# R7KA8P1AD register map
Vendor: Renesas Electronics Corporation; Series: RA8; File version: 1.10.02
CPU: CM85 r0p2, little endian, MPU, FPU, VTOR, 4 interrupt priority bits, 96 interrupts
Registers are 32-bit, read-write, reset 0x0 unless marked. A register's access mark holds for its fields unless they carry their own. Offsets are from the block's base; [hi:lo] are bit positions; lines under a group give offsets from that group; {n}, {i} and the like mark numbered series; 'fields as' and 'values as' point back to an identical list.

## RMAC0 — Ethernet MAC
Base 0x403CB000
Same registers: RMAC1 0x403CD000, RMAC0_NS 0x503CB000, RMAC1_NS 0x503CD000
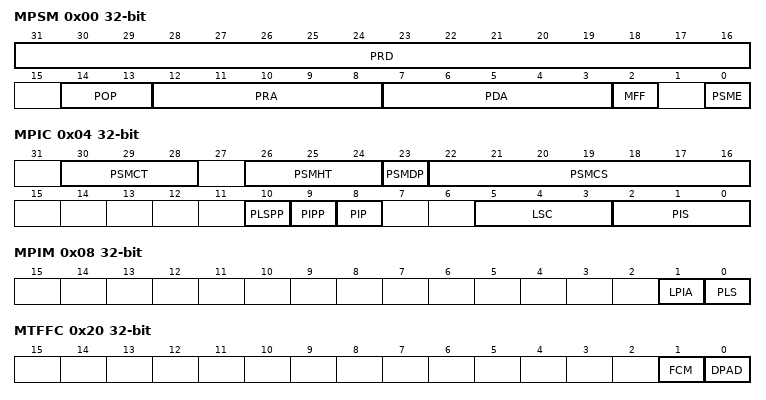
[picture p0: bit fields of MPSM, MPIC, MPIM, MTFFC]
0x00 MPSM — PHY Station Management Register
  [31:16] PRD — PHY Register Data
  [14:13] POP — PHY Operation Code
    1=Write Frame; 2=Read Frame; other=Others (Reserved(0 0 or 1 1 should not be set when MPSM.MFF = 0))
  [12:8] PRA — PHY Register Address
  [7:3] PDA — PHY Device Address
  [2] MFF — Management Frame Format
    0=Normal management frame format defined in Clause 22 of IEEE802.3 Describe “MDIO” in this document; 1=Extension management frame format defined in Clause 45 of IEEE802.3 Describe “eMDIO” in this document
  [0] PSME — PHY Station Management Enable
    0=PHY register access is not on progress; 1=PHY register access is requested and on progress
0x04 MPIC — PHY Interfaces Configuration Register
  [30:28] PSMCT — PHY Station Management Capture Time Adjustment
    0=No adjusted capture time (i.e. capture MDI at the rising edge of MDC); 1=Capture before 1 clk cycle
  [26:24] PSMHT — PHY Station Management Hold Time Adjustment
    0=No adjusted hold time (i.e. change MDO at the rising edge of MDC); 1=1 clk cycle extra hold time
  [23] PSMDP — PHY Station Management Disable Preamble
    0=PHY Station Management Preamble enabled; 1=PHY Station Management Preamble disabled
  [22:16] PSMCS — PHY Station Management Clock Selection
  [10] PLSPP — PHY Link Status Pin Plugged
    0=Unplugged; 1=Plugged
  [9] PIPP — PHY Interrupt Pin Plugged
    0=Unplugged; 1=Plugged
  [8] PIP — PHY Interrupt Polarity
    0=PHY interrupt is active low (default); 1=PHY interrupt is active high
  [5:3] LSC — Link Speed Configuration
    0=10mbps; 1=100mbps; 2=1gbps
  [2:0] PIS — PHY Interface Select
    0=MII; 2=GMII
0x08 MPIM ro — PHY Interfaces Monitoring Register
  [1] LPIA — LPI Active
    0=No LPI; 1=LPI active
  [0] PLS — PHY Link Status Flag
    0=PHY link signal is at the low level; 1=PHY link signal is at the high level
0x10 MIOC — I/O Configuration Register
  [0] MIOC0 — I/O Configuration 0
    0=Normal mode. clk_phy_tx and clk_phy_rx are provided.; 1=Emergency clock recovery mode. clk_phy_tx and clk_phy_rx are provided free-run clock (clk_common). (So transmission is not possible in this state.)
0x20 MTFFC — Transmission Frame Format Configuration Register
  [1] FCM — Flow Control Mode
    0=PAUSE; 1=PFC
  [0] DPAD — Data Padding Disable
    0=Padding is inserted; 1=Padding is not inserted
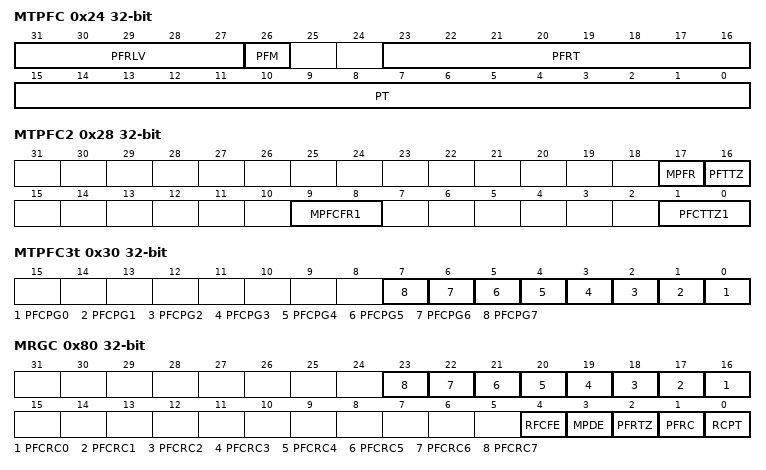
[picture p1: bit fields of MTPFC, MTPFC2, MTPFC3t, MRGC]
0x24 MTPFC — Transmission Pause or PFC Frame Configuration Register
  [31:27] PFRLV — Pause or PFC Frame Retry Limit Value
  [26] PFM — Pause Frame Mode
    0=Automatic pause frame. Sending a pause frame will be triggered by a hardware pause request.; 1=Manual pause frame. Sending a Pause frame will be triggered by MTPFC2.MPFR or MTPFC2.MPFCFR.
  [23:16] PFRT — Pause Frame Retransmission Time
  [15:0] PT — Pause Time
0x28 MTPFC2 — Transmission Pause or PFC Frame Configuration Register 2
  [17] MPFR — Manual Pause Frame Request
  [16] PFTTZ — Pause Frame Transmission with TIME = 0
    0=The transmission of Pause frames with TIME value zero is disabled; 1=The transmission of Pause frames with TIME value zero is enabled
  [9:8] MPFCFR1 to MPFCFR0 — Manual PFC Frame n Request (n = 0, 1)
  [1:0] PFCTTZ1 to PFCTTZ0 — PFC Frame n Transmission with TIME = 0 (n = 0, 1)
    0=The transmission of PFC frames with TIME value zero is disabled; 1=The transmission of PFC frames with TIME value zero is enabled
0x30 MTPFC3t — Transmission Pause or PFC Frame Configuration Register 3 for Priority Group t
  [all] fields
    0=Priority x is not assigned to priority group t; 1=Priority x is assigned to group t
  [n] PFCPG{n} (n=0..7) — PFC Priority Enable n (n = 0 to 7)
0x80 MRGC — Reception General Configuration Register
  [n+16] PFCRC{n} (n=0..7) — PFC Frame Reception Control n (n = 0 to 7)
    0=Flow control for the receiving priority level x (8) is disabled; 1=Flow control for the receiving priority level x (8) is enabled
  [4] RFCFE — Reception Flow Control Forwarding Enable
    0=Flow Control Frame (PAUSE or PFC frame) is not forward to Rx MHD I/F; 1=Flow Control Frame (PAUSE or PFC frame) is forward to Rx MHD I/F
  [3] MPDE — Magic Packet Detection Enable
    0=Magic Packet detection is disabled; 1=Magic Packet detection is enabled
  [2] PFRTZ — Pause or PFC Frame Reception with Time = 0
    0=Reception of Pause or PFC frames with the TIME value 0 is disabled; 1=Reception of Pause or PFC frames with the TIME value 0 is enabled
  [1] PFRC — Pause Frame Reception Control
    0=Flow control for the receiving port is disabled; 1=Flow control for the receiving port is enabled
  [0] RCPT — Receive CRC Pass Through
    0=Correct FCS is not passed to the MHD. Incorrect FCS is passed to the MHD.; 1=Both Correct and Incorrect FCS are passed to the MHD
0x84 MRMAC0 — Reception MAC Address Configuration Register 0
  [15:0] MAU — MAC Address Upper Part
0x88 MRMAC1 — Reception MAC Address Configuration Register 1
  [31:0] MAL — MAC Address Lower Part
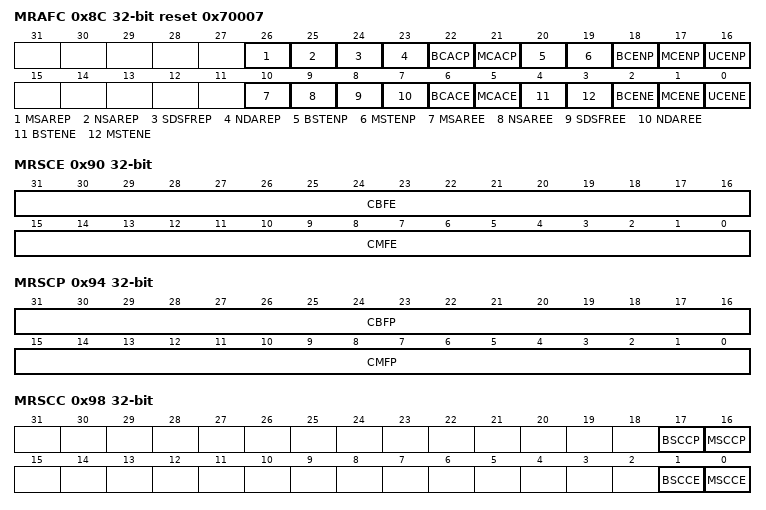
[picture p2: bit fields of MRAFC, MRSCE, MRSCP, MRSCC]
0x8C MRAFC reset 0x70007 — Reception Address Filter Configuration Register
  [26] MSAREP — Multicast Source Address Reception Enable P-Frames
    0=disable; 1=enable
  [25] NSAREP — Null Source Address Reception Enable P-Frames
    0=disable; 1=enable
  [24] SDSFREP — Same DA and SA Frames Reception Enable P-Frames
    0=disable; 1=enable
  [23] NDAREP — Null Destination Address Reception Enable P-Frames
    0=disable; 1=enable
  [22] BCACP — Broadcast Storm Autoclear P-Frames
    0=Broadcast Storm Autoclear disabled; 1=Broadcast Storm Autoclear enabled
  [21] MCACP — Multicast Storm Autoclear P-Frames
    0=Multicast Storm Autoclear disabled; 1=Multicast Storm Autoclear enabled
  [20] BSTENP — Broadcast Storm Filter Reception Enable P-Frames
    0=Broadcast storm filter reception disabled; 1=Broadcast storm filter reception enabled
  [19] MSTENP — Multicast Storm Filter Reception Enable P-Frames
    0=Multicast storm filter reception disabled; 1=Multicast storm filter reception enabled
  [18] BCENP — Broadcast Reception Enable P-Frames
    0=Broadcast reception disabled; 1=Broadcast reception enabled
  [17] MCENP — Multicast Reception Enable P-Frames
    0=Multicast reception disabled; 1=Multicast reception enabled
  [16] UCENP — Unicast Reception Enable P-Frames
    0=Unicast reception disabled; 1=Unicast reception enabled
  [10] MSAREE — Multicast Source Address Reception Enable E-Frames
    0=disable; 1=enable
  [9] NSAREE — Null Source Address Reception Enable E-Frames
    0=disable; 1=enable
  [8] SDSFREE — Same DA and SA Frames Reception Enable E-Frames
    0=disable; 1=enable
  [7] NDAREE — Null Destination Address Reception Enable E-Frames
    0=disable; 1=enable
  [6] BCACE — Broadcast Storm Autoclear E-Frames
    values as BCACP
  [5] MCACE — Multicast Storm Autoclear E-Frames
    values as MCACP
  [4] BSTENE — Broadcast Storm Filter Reception Enable E-Frames
    values as BSTENP
  [3] MSTENE — Multicast Storm Filter Reception Enable E-Frames
    values as MSTENP
  [2] BCENE — Broadcast Reception Enable E-Frames
    values as BCENP
  [1] MCENE — Multicast Reception Enable E-Frames
    values as MCENP
  [0] UCENE — Unicast Reception Enable E-Frames
    0=Unicast reception disabled; 1=Unicast reception enabled
0x90 MRSCE — Reception Storm Configuration for E-Frames Register
  [31:16] CBFE — Consecutive Broadcast Frame Reception Count Setting for E-Frames
  [15:0] CMFE — Consecutive Multicast Frame Reception Count Setting for E-Frames
0x94 MRSCP — Reception Storm Configuration for P-Frames Register
  [31:16] CBFP — Consecutive Broadcast Frame Reception Count Setting for P-Frames
  [15:0] CMFP — Consecutive Multicast Frame Reception Count Setting for P-Frames
0x98 MRSCC ro — Reception Storm Counter Configuration Register
  [17] BSCCP — Broadcast Storm Counter Clear P-Frames
  [16] MSCCP — Multicast Storm Counter Clear P-Frames
  [1] BSCCE — Broadcast Storm Counter Clear E-Frames
  [0] MSCCE — Multicast Storm Counter Clear E-Frames
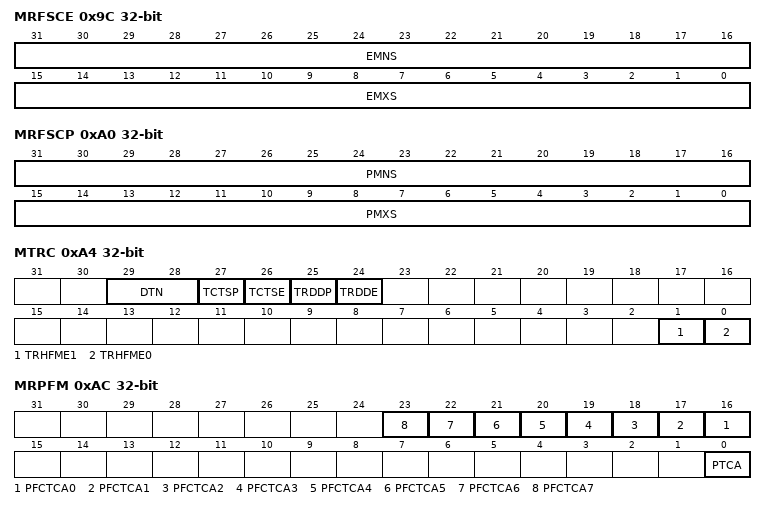
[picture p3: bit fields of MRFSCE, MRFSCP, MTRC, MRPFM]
0x9C MRFSCE — Reception Frame Size Configuration for E-Frames Register
  [31:16] EMNS — E-Frame Minimum Size
  [15:0] EMXS — E-Frame Maximum Size
0xA0 MRFSCP — Reception Frame Size Configuration for P-Frames Register
  [31:16] PMNS — P-Frame Minimum Size
  [15:0] PMXS — P-Frame Maximum Size
0xA4 MTRC — Timestamp Reception Configuration Register
  [29:28] DTN — Default Timer Number
  [27] TCTSP — Timestamp Capture on TX Side P-Frame
    0=disable; 1=enable
  [26] TCTSE — Timestamp Capture on TX Side E-Frame
    0=disable; 1=enable
  [25] TRDDP — Timestamp Reception Default Disable P-Frame
    0=enable; 1=disable
  [24] TRDDE — Timestamp Reception Default Disable E-Frame
    0=enable; 1=disable
  [1] TRHFME1 — Timestamp Reception Hardware Filter Match Enable n (n = 0 to 1)
    0=disable; 1=enable
  [0] TRHFME0 — Timestamp Reception Hardware Filter Match Enable n (n = 0 to 1)
    0=disable; 1=enable
0xAC MRPFM ro — Reception Pause or PFC Frame Monitoring Register
  [all] fields
    0=No pause state; 1=Pause state
  [n+16] PFCTCA{n} (n=0..7) — PFC Time Counting Active n (n = 0 to 7)
  [0] PTCA — Pause Time Counting Active
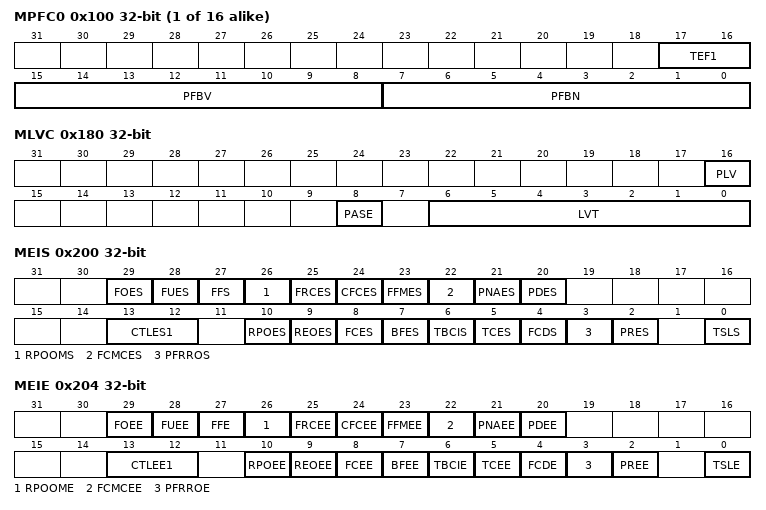
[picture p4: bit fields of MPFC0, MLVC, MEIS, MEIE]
{0x100+4i} MPFC{i} (i=0..15) — PTP Filtering Register Configuration Register {i}
  [17:16] TEF1 to TEF0 — Timer Enable for Filtering n (n = 0 to 1)
  [15:8] PFBV — PTP Filtering Byte Value
  [7:0] PFBN — PTP Filtering Byte Number
0x180 MLVC — Link Verification Configuration Register
  [16] PLV — Preemption Link Verification
    0=Preemption Link Verification not requested; 1=Preemption Link Verification requested
  [8] PASE — Preemption Auto Response Enable
  [6:0] LVT — Link Verification Timer
0x184 MEEEC — Energy Efficient Ethernet Configuration Register
  [0] LPITR — LPI Transmit Request
    0=LPI mode is not requested; 1=LPI mode is requested
0x188 MLBC — Loopback Configuration Register
  [0] LBME — Loopback Mode Enable
    0=disable; 1=enable
0x200 MEIS — Error Interrupt Status Register
  [29] FOES — Oversize Error Status Flag
  [28] FUES — Undersize Error Status Flag
  [27] FFS — Frame Filtered Status Flag
  [26] RPOOMS — Reception Partially out of Operation Mode Status Flag
  [25] FRCES — Fragment Count Error Status Flag
  [24] CFCES — C Fragment Count Error Status Flag
  [23] FFMES — Final Fragment Missing Error Status Flag
  [22] FCMCES — FCS/mCRC Error Status Flag
  [21] PNAES — PHY Nibble Alignment Error Status Flag
  [20] PDES — PHY Data Error Status Flag
  [13:12] CTLES1 to CTLES0 — Captured Timestamp Lost Error Status Flag n (n = 0 to 1)
  [10] RPOES — P-Frame Overflow Error Status Flag
    0=No overflow error; 1=Overflow error occurred during p-frame reception
  [9] REOES — E-Frame Overflow Error Status Flag
    0=No overflow error; 1=Overflow error occurred during e-frame reception
  [8] FCES — Frame Count Error Status Flag
  [7] BFES — Bad Fragment Error Status Flag
  [6] TBCIS — TX Bad CRC Insertion Status Flag
  [5] TCES — TX CRC Error Status Flag
  [4] FCDS — False Carrier Detection Status Flag
  [3] PFRROS — Pause or PFC Frame Retransmit Retry Over Status Flag
  [2] PRES — Pause or PFC Frame Reception Error Status Flag
  [0] TSLS — Transmission Stream Lost Status Flag
0x204 MEIE — Error Interrupt Enable Register
  [29] FOEE — Oversize Error Enable
  [28] FUEE — Undersize Error Enable
  [27] FFE — Frame Filtered Enable
  [26] RPOOME — Reception Partially out of Operation Mode Enable
  [25] FRCEE — Fragment Count Error Enable
  [24] CFCEE — C Fragment Count Error Enable
  [23] FFMEE — Final Fragment Missing Error Enable
  [22] FCMCEE — FCS/mCRC Error Enable
  [21] PNAEE — PHY Nibble Alignment Error Enable
  [20] PDEE — PHY Data Error Enable
  [13:12] CTLEE1 to CTLEE0 — Captured Timestamp Lost Error Enable n (n = 0 to 1)
  [10] RPOEE — P-Frame Overflow Error Enable
  [9] REOEE — E-Frame Overflow Error Enable
  [8] FCEE — Frame Count Error Enable
  [7] BFEE — Bad Fragment Error Enable
  [6] TBCIE — TX Bad CRC Insertion Enable
  [5] TCEE — Tx CRC Error Enable
  [4] FCDE — False Carrier Detection Enable
  [3] PFRROE — Pause or PFC Frame Retransmit Retry Over Enable
  [2] PREE — Pause or PFC Frame Reception Error Enable
  [0] TSLE — Transmission Stream Lost Enable
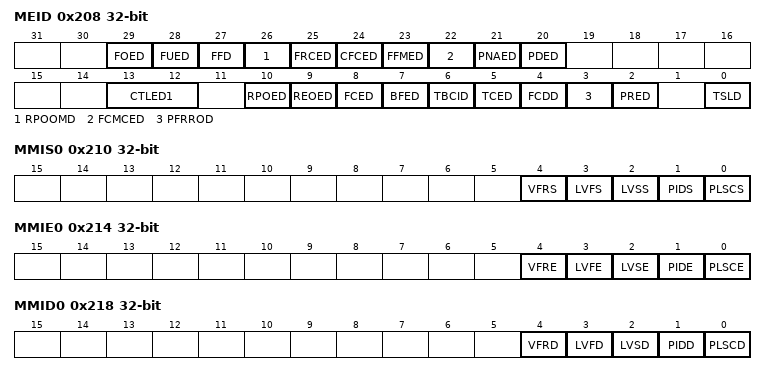
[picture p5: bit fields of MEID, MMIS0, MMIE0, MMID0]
0x208 MEID — Error Interrupt Disable Register
  [29] FOED — Oversize Error Disable
  [28] FUED — Undersize Error Disable
  [27] FFD — Frame Filtered Disable
  [26] RPOOMD — Reception Partially out of Operation Mode Disable
  [25] FRCED — Fragment Count Error Disable
  [24] CFCED — C Fragment Count Error Disable
  [23] FFMED — Final Fragment Missing Error Disable
  [22] FCMCED — FCS/mCRC Error Disable
  [21] PNAED — PHY Nibble Alignment Error Disable
  [20] PDED — PHY Data Error Disable
  [13:12] CTLED1 to CTLED0 — Captured Timestamp Lost Error Disable n (n = 0 to 1)
  [10] RPOED — P-Frame Overflow Error Disable
  [9] REOED — E-Frame Overflow Error Disable
  [8] FCED — Frame Count Error Disable
  [7] BFED — Bad Fragment Error Disable
  [6] TBCID — TX Bad CRC Insertion Disable
  [5] TCED — Tx CRC Error Disable
  [4] FCDD — False Carrier Detection Disable
  [3] PFRROD — Pause or PFC Frame Retransmit Retry Over Disable
  [2] PRED — Pause or PFC Frame Reception Error Disable
  [0] TSLD — Transmission Stream Lost Disable
0x210 MMIS0 — Monitoring Interrupt Status Register 0
  [4] VFRS — Verify Frame Reception Status Flag
  [3] LVFS — Link Verification Failed Status Flag
  [2] LVSS — Link Verification Succeed Status Flag
  [1] PIDS — PHY Interrupt Detection Status Flag
  [0] PLSCS — PHY Link Signal Change Status Flag
0x214 MMIE0 — Monitoring Interrupt Enable Register 0
  [4] VFRE — Verify Frame Reception Enable
  [3] LVFE — Link Verification Failed Enable
  [2] LVSE — Link Verification Succeed Enable
  [1] PIDE — PHY Interrupt Detection Enable
  [0] PLSCE — PHY Link Signal Change Enable
0x218 MMID0 — Monitoring Interrupt Disable Register 0
  [4] VFRD — Verify Frame Reception Disable
  [3] LVFD — Link Verification Failed Disable
  [2] LVSD — Link Verification Succeed Disable
  [1] PIDD — PHY Interrupt Detection Disable
  [0] PLSCD — PHY Link Signal Change Disable
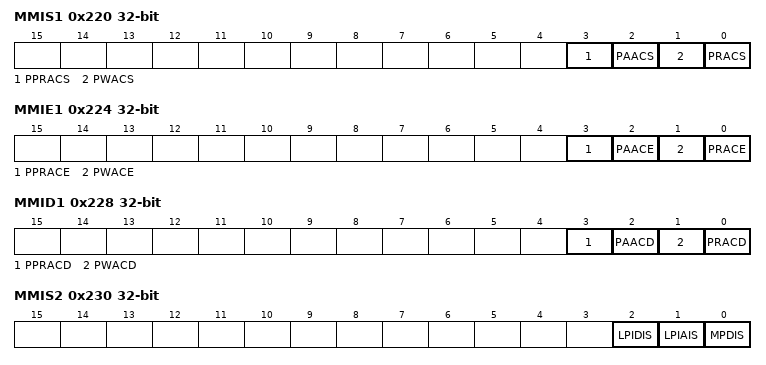
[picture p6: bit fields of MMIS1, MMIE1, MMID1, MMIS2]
0x220 MMIS1 — Monitoring Interrupt Status Register 1
  [3] PPRACS — PHY Post-Read Access Completed Status Flag
  [2] PAACS — PHY Address Access Completed Status Flag
  [1] PWACS — PHY Write Access Completed Status Flag
  [0] PRACS — PHY Read Access Completed Status Flag
0x224 MMIE1 — Monitoring Interrupt Enable Register 1
  [3] PPRACE — PHY Post-Read Access Completed Enable
  [2] PAACE — PHY Address Access Completed Enable
  [1] PWACE — PHY Write Access Completed Enable
  [0] PRACE — PHY Read Access Completed Enable
0x228 MMID1 — Monitoring Interrupt Disable Register 1
  [3] PPRACD wo — PHY Post-Read Access Completed Disable
  [2] PAACD wo — PHY Address Access Completed Disable
  [1] PWACD wo — PHY Write Access Completed Disable
  [0] PRACD wo — PHY Read Access Completed Disable
0x230 MMIS2 — Monitoring Interrupt Status Register 2
  [2] LPIDIS — LPI De-Assertion Interrupt Status Flag
  [1] LPIAIS — LPI Assertion Interrupt Status Flag
  [0] MPDIS — Magic Packet Detection Interrupt Status Flag
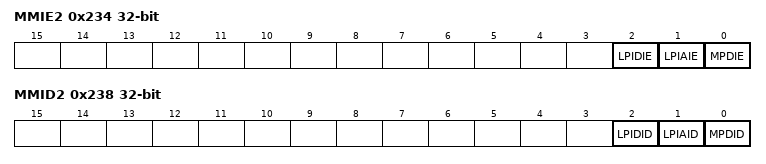
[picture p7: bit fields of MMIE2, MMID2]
0x234 MMIE2 — Monitoring Interrupt Enable Register 2
  [2] LPIDIE — LPI De-Assertion Interrupt Enable
  [1] LPIAIE — LPI Assertion Interrupt Enable
  [0] MPDIE — Magic Packet Detection Interrupt Enable
0x238 MMID2 — Monitoring Interrupt Disable Register 2
  [2] LPIDID wo — LPI De-Assertion Interrupt Disable
  [1] LPIAID wo — LPI Assertion Interrupt Disable
  [0] MPDID wo — Magic Packet Detection Interrupt Disable
0x300 MMPFTCT ro — Manual Pause Frame Transmit Counter Register
  [15:0] MPFTC — Manual Pause frame Transmit Counter
0x304 MAPFTCT ro — Automatic Pause Frame Transmit Counter Register
  [15:0] APFTC — Automatic pause Frame Counter
0x308 MPFRCT ro — Pause Frame Receive Counter Register
  [15:0] PFRC — Pause Frame Receive Counter
0x30C MFCICT ro — False Carrier Indication Counter Register
  [15:0] FCIC — False Carrier Indication Counter
0x310 MEEECT ro — Energy Efficient Ethernet Counter Register
  [15:0] EEERC — Energy Efficient Ethernet Receive Counter
{0x320+4i} MMPCFTCT{i} (i=0..1) ro — Manual PFC Frame Transmit Counter Register
  [15:0] MPCFCTC — Manual PFC frame Transmit Counter
{0x330+4i} MAPCFTCT{i} (i=0..1) ro — Automatic PFC Frame Transmit Counter Register
  [15:0] APCFCTC — Automatic PFC Frame Counter
{0x340+4i} MPCFRCT{i} (i=0..1) ro — PFC Frame Receive Counter Register
  [15:0] PCFCRC — PFC Frame Receive Counter
0x360 MROVFC ro — Receive Overflow Counter Register
  [31:0] ROVFC — Receive overflow counter
0x408 MRGFCE ro — Received Good Frame Counter E-Frames Register
  [31:0] RGFNE — Received good frame number E-frames
0x40C MRGFCP ro — Received Good Frame Counter P-Frames Register
  [31:0] GFNP — Received good frame number P-frames
0x410 MRBFC ro — Received Good Broadcast Frame Counter Register
  [31:0] RBFN — Received good broadcast frame number
0x414 MRMFC ro — Received Good Multicast Frame Counter Register
  [31:0] RMFN — Received good multicast frame number
0x418 MRUFC ro — Received Good Unicast Frame Counter Register
  [31:0] RUFN — Received good unicast frame number
0x41C MRPEFC ro — Received PHY Error Frame Count Register
  [15:0] RPEFN — Received PHY error frame number
0x420 MRNEFC ro — Received Nibble Error Frame Count Register
  [15:0] RNEFN — Received nibble error frame number
0x424 MRFMEFC ro — Received FCS/mCRC Error Frame Count Register
  [31:0] RFMEFN — Received FCS/mCRC error frame number
0x428 MRFFMEFC ro — Received Final Fragment Missing Error Frame Count Register
  [15:0] RFFMEFN — Received final fragment missing error frame number
0x42C MRCFCEFC ro — Received C-Fragment Count Error Frame Count Register
  [15:0] RCFCEFN — Received C-fragment count error frame number
0x430 MRFCEFC ro — Received Fragment Count Error Frame Count Register
  [15:0] RFCEFN — Received fragment count error frame number
0x434 MRRCFEFC ro — Received RMAC Filter Error Frame Count Register
  [15:0] RRCFEFN — Received RMAC filter error frame number
0x438 MRFC ro — Received Frame Count Register
  [31:0] RFN — Received frame number
0x43C MRGUEFC ro — Received Good Undersize Error Frame Count Register
  [31:0] RUEFN — Received good undersize error frame number
0x440 MRBUEFC ro — Received Bad Undersize Error Frame Count Register
  [31:0] RUEFN — Received bad undersize error frame number
0x444 MRGOEFC ro — Received Good Oversize Error Frame Count Register
  [31:0] RGOEFN — Received good oversize error frame number
0x448 MRBOEFC ro — Received Bad Oversize Error Frame Count Register
  [31:0] RBOEFN — Received bad oversize error frame number
0x44C MRXBCEU ro — Received Byte Counter E-Frames Upper Side Register
  [31:0] RBNEU — Received byte number E-frames upper side
0x450 MRXBCEL ro — Received Byte Counter E-Frames Lower Side Register
  [31:0] RBNEL — Received byte number E-frames lower side
0x454 MRXBCPU ro — Received Byte Counter P-Frames Upper Side Register
  [31:0] RBNPU — Received byte number P-frames upper side
0x458 MRXBCPL ro — Received Byte Counter P-Frames Lower Side Register
  [31:0] RBNPL — Received byte number P-frames lower side
0x508 MTGFCE ro — Transmitted Good Frame Counter E-Frames Register
  [31:0] TGFNE — Transmitted good frame number E-frames
0x50C MTGFCP ro — Transmitted Good Frame Counter P-Frames Register
  [31:0] TGFNP — Transmitted good frame number P-frames
0x510 MTBFC ro — Transmitted Broadcast Frame Counter Register
  [31:0] TBFN — Transmitted broadcast frame number
0x514 MTMFC ro — Transmitted Multicast Frame Counter Register
  [31:0] TMFN — Transmitted multicast frame number
0x518 MTUFC ro — Transmitted Unicast Frame Counter Register
  [31:0] TUFN — Transmitted unicast frame number
0x51C MTEFC ro — Transmitted Error Frame Counter Register
  [15:0] TEFN — Transmitted error frame number
0x520 MTXBCEU ro — Transmitted Byte Counter E-Frames Upper Side Register
  [31:0] TBNEU — Transmitted byte number E-frames upper side
0x524 MTXBCEL ro — Transmitted Byte Counter E-Frames Lower Side Register
  [31:0] TBNEL — Transmitted byte number E-frames lower side
0x528 MTXBCPU ro — Transmitted Byte Counter P-Frames Upper Side Register
  [31:0] TBNPU — Transmitted byte number P-frames upper side
0x52C MTXBCPL ro — Transmitted Byte Counter P-Frames Lower Side Register
  [31:0] TBNPL — Transmitted byte number P-frames lower side
